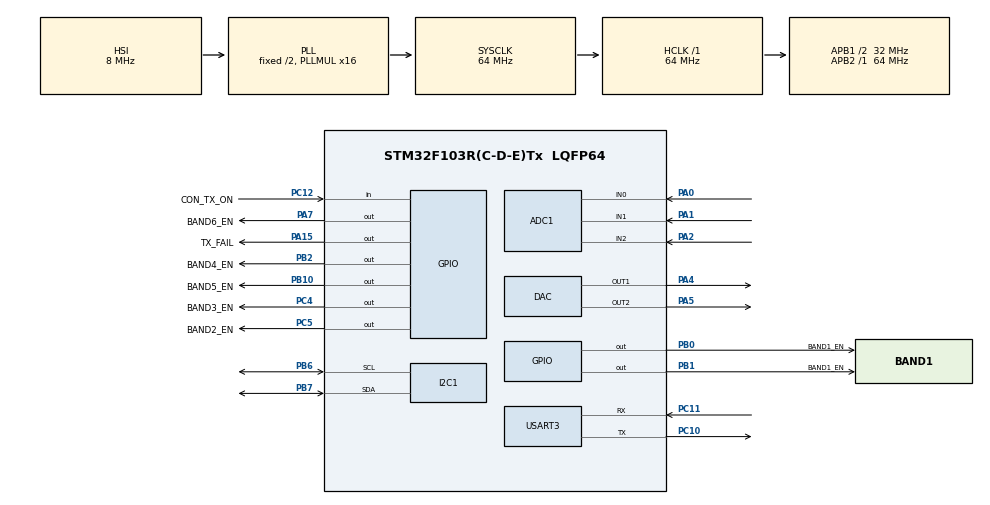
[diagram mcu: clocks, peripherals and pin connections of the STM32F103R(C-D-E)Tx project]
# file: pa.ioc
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ADC1.Channel-0\#ChannelRegularConversion=ADC_CHANNEL_0
ADC1.Channel-1\#ChannelRegularConversion=ADC_CHANNEL_0
ADC1.Channel-2\#ChannelRegularConversion=ADC_CHANNEL_0
ADC1.ExternalTrigConv=ADC_EXTERNALTRIGCONV_T3_TRGO
ADC1.NbrOfConversion=3
ADC1.NbrOfConversionFlag=1
ADC1.Rank-0\#ChannelRegularConversion=1
ADC1.Rank-1\#ChannelRegularConversion=2
ADC1.Rank-2\#ChannelRegularConversion=3
ADC1.SamplingTime-0\#ChannelRegularConversion=ADC_SAMPLETIME_13CYCLES_5
ADC1.SamplingTime-1\#ChannelRegularConversion=ADC_SAMPLETIME_13CYCLES_5
ADC1.SamplingTime-2\#ChannelRegularConversion=ADC_SAMPLETIME_13CYCLES_5
ADC1.master=1
Dma.ADC1.0.Direction=DMA_PERIPH_TO_MEMORY
Dma.ADC1.0.Instance=DMA1_Channel1
Dma.ADC1.0.MemDataAlignment=DMA_MDATAALIGN_HALFWORD
Dma.ADC1.0.MemInc=DMA_MINC_ENABLE
Dma.ADC1.0.Mode=DMA_CIRCULAR
Dma.ADC1.0.PeriphDataAlignment=DMA_PDATAALIGN_HALFWORD
Dma.ADC1.0.PeriphInc=DMA_PINC_DISABLE
Dma.ADC1.0.Priority=DMA_PRIORITY_LOW
Dma.Request0=ADC1
Dma.Request1=USART3_RX
Dma.Request2=USART3_TX
Dma.USART3_RX.1.Direction=DMA_PERIPH_TO_MEMORY
Dma.USART3_RX.1.Instance=DMA1_Channel3
Dma.USART3_RX.1.MemDataAlignment=DMA_MDATAALIGN_BYTE
Dma.USART3_RX.1.MemInc=DMA_MINC_ENABLE
Dma.USART3_RX.1.Mode=DMA_CIRCULAR
Dma.USART3_RX.1.PeriphDataAlignment=DMA_PDATAALIGN_BYTE
Dma.USART3_RX.1.PeriphInc=DMA_PINC_DISABLE
Dma.USART3_RX.1.Priority=DMA_PRIORITY_LOW
Dma.USART3_TX.2.Direction=DMA_MEMORY_TO_PERIPH
Dma.USART3_TX.2.Instance=DMA1_Channel2
Dma.USART3_TX.2.MemDataAlignment=DMA_MDATAALIGN_BYTE
Dma.USART3_TX.2.MemInc=DMA_MINC_ENABLE
Dma.USART3_TX.2.Mode=DMA_NORMAL
Dma.USART3_TX.2.PeriphDataAlignment=DMA_PDATAALIGN_BYTE
Dma.USART3_TX.2.PeriphInc=DMA_PINC_DISABLE
Dma.USART3_TX.2.Priority=DMA_PRIORITY_LOW
Mcu.Family=STM32F1
Mcu.Name=STM32F103R(C-D-E)Tx
Mcu.Package=LQFP64
NVIC.ADC1_2_IRQn=true\:5\:0\:true\:false\:true\:true\:true\:true
NVIC.DMA1_Channel1_IRQn=true\:5\:0\:true\:false\:true\:false\:true\:true
NVIC.DMA1_Channel2_IRQn=true\:6\:0\:true\:false\:true\:false\:true\:true
NVIC.DMA1_Channel3_IRQn=true\:6\:0\:true\:false\:true\:false\:true\:true
NVIC.I2C1_ER_IRQn=true\:7\:0\:true\:false\:true\:true\:true\:true
NVIC.I2C1_EV_IRQn=true\:7\:0\:true\:false\:true\:true\:true\:true
NVIC.PriorityGroup=NVIC_PRIORITYGROUP_4
PA0-WKUP.Signal=ADCx_IN0
PA1.Signal=ADCx_IN1
PA13.Mode=Trace_Asynchronous_SW
PA13.Signal=SYS_JTMS-SWDIO
PA14.Mode=Trace_Asynchronous_SW
PA14.Signal=SYS_JTCK-SWCLK
PA15.GPIO_Label=TX_FAIL
PA15.Signal=GPIO_Output
PA2.Signal=ADCx_IN2
PA4.Signal=COMP_DAC1_group
PA5.Signal=COMP_DAC2_group
PA7.GPIO_Label=BAND6_EN
PA7.Signal=GPIO_Output
PB0.GPIO_Label=BAND1_EN
PB0.Signal=GPIO_Output
PB1.GPIO_Label=BAND1_EN
PB1.Signal=GPIO_Output
PB10.GPIO_Label=BAND5_EN
PB10.Signal=GPIO_Output
PB2.GPIO_Label=BAND4_EN
PB2.Signal=GPIO_Output
PB3.Mode=Trace_Asynchronous_SW
PB3.Signal=SYS_JTDO-TRACESWO
PB6.Mode=I2C
PB6.Signal=I2C1_SCL
PB7.Mode=I2C
PB7.Signal=I2C1_SDA
PC10.Mode=Asynchronous
PC10.Signal=USART3_TX
PC11.Mode=Asynchronous
PC11.Signal=USART3_RX
PC12.GPIO_Label=CON_TX_ON
PC12.Signal=GPIO_Input
PC4.GPIO_Label=BAND3_EN
PC4.Signal=GPIO_Output
PC5.GPIO_Label=BAND2_EN
PC5.Signal=GPIO_Output
ProjectManager.HeapSize=0x200
ProjectManager.StackSize=0x400
ProjectManager.TargetToolchain=STM32CubeIDE
RCC.ADCPresc=RCC_ADCPCLK2_DIV8
RCC.AHBFreq_Value=64000000
RCC.APB1CLKDivider=RCC_HCLK_DIV2
RCC.APB1Freq_Value=32000000
RCC.APB1TimFreq_Value=64000000
RCC.APB2Freq_Value=64000000
RCC.APB2TimFreq_Value=64000000
RCC.HCLKFreq_Value=64000000
RCC.PLLMUL=RCC_PLL_MUL16
RCC.SYSCLKFreq_VALUE=64000000
RCC.SYSCLKSource=RCC_SYSCLKSOURCE_PLLCLK
RCC.USBFreq_Value=64000000
SH.ADCx_IN0.0=ADC1_IN0,IN0
SH.ADCx_IN1.0=ADC1_IN1,IN1
SH.ADCx_IN2.0=ADC1_IN2,IN2
SH.COMP_DAC1_group.0=DAC_OUT1,DAC_OUT1
SH.COMP_DAC2_group.0=DAC_OUT2,DAC_OUT2
TIM3.TIM_MasterOutputTrigger=TIM_TRGO_UPDATE
USART3.VirtualMode=VM_ASYNC
VP_TIM3_VS_ClockSourceINT.Mode=Internal
board=custom

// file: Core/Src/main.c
/* USER CODE BEGIN Header */
/**
  ******************************************************************************
  * @file           : main.c
  * @brief          : Main program body
  ******************************************************************************
  * @attention
  *
  * Copyright (c) 2025 STMicroelectronics.
  * All rights reserved.
  *
  * This software is licensed under terms that can be found in the LICENSE file
  * in the root directory of this software component.
  * If no LICENSE file comes with this software, it is provided AS-IS.
  *
  ******************************************************************************
  */
/* USER CODE END Header */
#include "main.h"

/* USER CODE BEGIN Includes */
#include "cmd.h"
#include "adc.h"
#include "gpio.h"
#include "max6651.h"
/* USER CODE END Includes */

ADC_HandleTypeDef hadc1;
DMA_HandleTypeDef hdma_adc1;

DAC_HandleTypeDef hdac;

I2C_HandleTypeDef hi2c1;

TIM_HandleTypeDef htim3;

UART_HandleTypeDef huart3;
DMA_HandleTypeDef hdma_usart3_rx;
DMA_HandleTypeDef hdma_usart3_tx;

void SystemClock_Config(void);
static void MX_GPIO_Init(void);
static void MX_DMA_Init(void);
static void MX_ADC1_Init(void);
static void MX_DAC_Init(void);
static void MX_I2C1_Init(void);
static void MX_USART3_UART_Init(void);
static void MX_TIM3_Init(void);

int main(void)
{

  /* MCU Configuration--------------------------------------------------------*/

  /* Reset of all peripherals, Initializes the Flash interface and the Systick. */
  HAL_Init();

  /* Configure the system clock */
  SystemClock_Config();

  /* Initialize all configured peripherals */
  MX_GPIO_Init();
  MX_DMA_Init();
  MX_ADC1_Init();
  MX_DAC_Init();
  MX_I2C1_Init();
  MX_USART3_UART_Init();
  MX_TIM3_Init();
  /* USER CODE BEGIN 2 */
  gpio_tx_off();
  max6651_init();
  cmd_start();
  adc_start();

  HAL_DAC_SetValue(&hdac, DAC_CHANNEL_1, DAC_ALIGN_12B_R, 0);
  HAL_DAC_SetValue(&hdac, DAC_CHANNEL_2, DAC_ALIGN_12B_R, 0);
  HAL_DAC_Start(&hdac, DAC_CHANNEL_1);
  HAL_DAC_Start(&hdac, DAC_CHANNEL_2);

  /* USER CODE END 2 */
//  gpio_tx_on();
  /* Infinite loop */
  while (1)
  {

    /* USER CODE BEGIN 3 */
	  cmd_tick();
	  adc_tick();
	  gpio_tick();
	  max6651_tick();
  }
  /* USER CODE END 3 */
}

void SystemClock_Config(void)
{
  RCC_OscInitTypeDef RCC_OscInitStruct = {0};
  RCC_ClkInitTypeDef RCC_ClkInitStruct = {0};
  RCC_PeriphCLKInitTypeDef PeriphClkInit = {0};

  /** Initializes the RCC Oscillators according to the specified parameters
  * in the RCC_OscInitTypeDef structure.
  */
  RCC_OscInitStruct.OscillatorType = RCC_OSCILLATORTYPE_HSI;
  RCC_OscInitStruct.HSIState = RCC_HSI_ON;
  RCC_OscInitStruct.HSICalibrationValue = RCC_HSICALIBRATION_DEFAULT;
  RCC_OscInitStruct.PLL.PLLState = RCC_PLL_ON;
  RCC_OscInitStruct.PLL.PLLSource = RCC_PLLSOURCE_HSI_DIV2;
  RCC_OscInitStruct.PLL.PLLMUL = RCC_PLL_MUL16;
  if (HAL_RCC_OscConfig(&RCC_OscInitStruct) != HAL_OK)
  {
    Error_Handler();
  }

  /** Initializes the CPU, AHB and APB buses clocks
  */
  RCC_ClkInitStruct.ClockType = RCC_CLOCKTYPE_HCLK|RCC_CLOCKTYPE_SYSCLK
                              |RCC_CLOCKTYPE_PCLK1|RCC_CLOCKTYPE_PCLK2;
  RCC_ClkInitStruct.SYSCLKSource = RCC_SYSCLKSOURCE_PLLCLK;
  RCC_ClkInitStruct.AHBCLKDivider = RCC_SYSCLK_DIV1;
  RCC_ClkInitStruct.APB1CLKDivider = RCC_HCLK_DIV2;
  RCC_ClkInitStruct.APB2CLKDivider = RCC_HCLK_DIV1;

  if (HAL_RCC_ClockConfig(&RCC_ClkInitStruct, FLASH_LATENCY_2) != HAL_OK)
  {
    Error_Handler();
  }
  PeriphClkInit.PeriphClockSelection = RCC_PERIPHCLK_ADC;
  PeriphClkInit.AdcClockSelection = RCC_ADCPCLK2_DIV8;
  if (HAL_RCCEx_PeriphCLKConfig(&PeriphClkInit) != HAL_OK)
  {
    Error_Handler();
  }
}

static void MX_ADC1_Init(void)
{

  ADC_ChannelConfTypeDef sConfig = {0};

  /** Common config
  */
  hadc1.Instance = ADC1;
  hadc1.Init.ScanConvMode = ADC_SCAN_ENABLE;
  hadc1.Init.ContinuousConvMode = DISABLE;
  hadc1.Init.DiscontinuousConvMode = DISABLE;
  hadc1.Init.ExternalTrigConv = ADC_EXTERNALTRIGCONV_T3_TRGO;
  hadc1.Init.DataAlign = ADC_DATAALIGN_RIGHT;
  hadc1.Init.NbrOfConversion = 3;
  if (HAL_ADC_Init(&hadc1) != HAL_OK)
  {
    Error_Handler();
  }

  /** Configure Regular Channel
  */
  sConfig.Channel = ADC_CHANNEL_0;
  sConfig.Rank = ADC_REGULAR_RANK_1;
  sConfig.SamplingTime = ADC_SAMPLETIME_13CYCLES_5;
  if (HAL_ADC_ConfigChannel(&hadc1, &sConfig) != HAL_OK)
  {
    Error_Handler();
  }

  /** Configure Regular Channel
  */
  sConfig.Channel = ADC_CHANNEL_1;
  sConfig.Rank = ADC_REGULAR_RANK_2;
  if (HAL_ADC_ConfigChannel(&hadc1, &sConfig) != HAL_OK)
  {
    Error_Handler();
  }

  /** Configure Regular Channel
  */
  sConfig.Channel = ADC_CHANNEL_2;
  sConfig.Rank = ADC_REGULAR_RANK_3;
  if (HAL_ADC_ConfigChannel(&hadc1, &sConfig) != HAL_OK)
  {
    Error_Handler();
  }

}

static void MX_DAC_Init(void)
{

  DAC_ChannelConfTypeDef sConfig = {0};

  /** DAC Initialization
  */
  hdac.Instance = DAC;
  if (HAL_DAC_Init(&hdac) != HAL_OK)
  {
    Error_Handler();
  }

  /** DAC channel OUT1 config
  */
  sConfig.DAC_Trigger = DAC_TRIGGER_NONE;
  sConfig.DAC_OutputBuffer = DAC_OUTPUTBUFFER_ENABLE;
  if (HAL_DAC_ConfigChannel(&hdac, &sConfig, DAC_CHANNEL_1) != HAL_OK)
  {
    Error_Handler();
  }

  /** DAC channel OUT2 config
  */
  if (HAL_DAC_ConfigChannel(&hdac, &sConfig, DAC_CHANNEL_2) != HAL_OK)
  {
    Error_Handler();
  }

}

static void MX_I2C1_Init(void)
{

  hi2c1.Instance = I2C1;
  hi2c1.Init.ClockSpeed = 100000;
  hi2c1.Init.DutyCycle = I2C_DUTYCYCLE_2;
  hi2c1.Init.OwnAddress1 = 0;
  hi2c1.Init.AddressingMode = I2C_ADDRESSINGMODE_7BIT;
  hi2c1.Init.DualAddressMode = I2C_DUALADDRESS_DISABLE;
  hi2c1.Init.OwnAddress2 = 0;
  hi2c1.Init.GeneralCallMode = I2C_GENERALCALL_DISABLE;
  hi2c1.Init.NoStretchMode = I2C_NOSTRETCH_DISABLE;
  if (HAL_I2C_Init(&hi2c1) != HAL_OK)
  {
    Error_Handler();
  }

}

static void MX_TIM3_Init(void)
{

  TIM_ClockConfigTypeDef sClockSourceConfig = {0};
  TIM_MasterConfigTypeDef sMasterConfig = {0};

  htim3.Instance = TIM3;
  htim3.Init.Prescaler = 0;
  htim3.Init.CounterMode = TIM_COUNTERMODE_UP;
  htim3.Init.Period = 65535;
  htim3.Init.ClockDivision = TIM_CLOCKDIVISION_DIV1;
  htim3.Init.AutoReloadPreload = TIM_AUTORELOAD_PRELOAD_DISABLE;
  if (HAL_TIM_Base_Init(&htim3) != HAL_OK)
  {
    Error_Handler();
  }
  sClockSourceConfig.ClockSource = TIM_CLOCKSOURCE_INTERNAL;
  if (HAL_TIM_ConfigClockSource(&htim3, &sClockSourceConfig) != HAL_OK)
  {
    Error_Handler();
  }
  sMasterConfig.MasterOutputTrigger = TIM_TRGO_UPDATE;
  sMasterConfig.MasterSlaveMode = TIM_MASTERSLAVEMODE_DISABLE;
  if (HAL_TIMEx_MasterConfigSynchronization(&htim3, &sMasterConfig) != HAL_OK)
  {
    Error_Handler();
  }

}

static void MX_USART3_UART_Init(void)
{

  huart3.Instance = USART3;
  huart3.Init.BaudRate = 115200;
  huart3.Init.WordLength = UART_WORDLENGTH_8B;
  huart3.Init.StopBits = UART_STOPBITS_1;
  huart3.Init.Parity = UART_PARITY_NONE;
  huart3.Init.Mode = UART_MODE_TX_RX;
  huart3.Init.HwFlowCtl = UART_HWCONTROL_NONE;
  huart3.Init.OverSampling = UART_OVERSAMPLING_16;
  if (HAL_UART_Init(&huart3) != HAL_OK)
  {
    Error_Handler();
  }

}

static void MX_DMA_Init(void)
{

  /* DMA controller clock enable */
  __HAL_RCC_DMA1_CLK_ENABLE();

  /* DMA interrupt init */
  /* DMA1_Channel1_IRQn interrupt configuration */
  HAL_NVIC_SetPriority(DMA1_Channel1_IRQn, 5, 0);
  HAL_NVIC_EnableIRQ(DMA1_Channel1_IRQn);
  /* DMA1_Channel2_IRQn interrupt configuration */
  HAL_NVIC_SetPriority(DMA1_Channel2_IRQn, 6, 0);
  HAL_NVIC_EnableIRQ(DMA1_Channel2_IRQn);
  /* DMA1_Channel3_IRQn interrupt configuration */
  HAL_NVIC_SetPriority(DMA1_Channel3_IRQn, 6, 0);
  HAL_NVIC_EnableIRQ(DMA1_Channel3_IRQn);

}

static void MX_GPIO_Init(void)
{
  GPIO_InitTypeDef GPIO_InitStruct = {0};

  /* GPIO Ports Clock Enable */
  __HAL_RCC_GPIOA_CLK_ENABLE();
  __HAL_RCC_GPIOC_CLK_ENABLE();
  __HAL_RCC_GPIOB_CLK_ENABLE();

  /*Configure GPIO pin Output Level */
  HAL_GPIO_WritePin(GPIOA, BAND6_EN_Pin|TX_FAIL_Pin, GPIO_PIN_RESET);

  /*Configure GPIO pin Output Level */
  HAL_GPIO_WritePin(GPIOC, BAND2_EN_Pin|BAND3_EN_Pin, GPIO_PIN_RESET);

  /*Configure GPIO pin Output Level */
  HAL_GPIO_WritePin(GPIOB, BAND0_EN_Pin|BAND1_EN_Pin|BAND4_EN_Pin|BAND5_EN_Pin, GPIO_PIN_RESET);

  /*Configure GPIO pins : BAND6_EN_Pin BAND5_EN_Pin TX_FAIL_Pin */
  GPIO_InitStruct.Pin = BAND6_EN_Pin|TX_FAIL_Pin;
  GPIO_InitStruct.Mode = GPIO_MODE_OUTPUT_PP;
  GPIO_InitStruct.Pull = GPIO_NOPULL;
  GPIO_InitStruct.Speed = GPIO_SPEED_FREQ_LOW;
  HAL_GPIO_Init(GPIOA, &GPIO_InitStruct);

  /*Configure GPIO pins : BAND4_EN_Pin BAND3_EN_Pin */
  GPIO_InitStruct.Pin = BAND2_EN_Pin|BAND3_EN_Pin;
  GPIO_InitStruct.Mode = GPIO_MODE_OUTPUT_PP;
  GPIO_InitStruct.Pull = GPIO_NOPULL;
  GPIO_InitStruct.Speed = GPIO_SPEED_FREQ_LOW;
  HAL_GPIO_Init(GPIOC, &GPIO_InitStruct);

  /*Configure GPIO pins : BAND2_EN_Pin BAND1_EN_Pin BAND0_EN_Pin */
  GPIO_InitStruct.Pin = BAND0_EN_Pin|BAND1_EN_Pin|BAND4_EN_Pin|BAND5_EN_Pin;
  GPIO_InitStruct.Mode = GPIO_MODE_OUTPUT_PP;
  GPIO_InitStruct.Pull = GPIO_NOPULL;
  GPIO_InitStruct.Speed = GPIO_SPEED_FREQ_LOW;
  HAL_GPIO_Init(GPIOB, &GPIO_InitStruct);

  /*Configure GPIO pin : CON_TX_ON_Pin */
  GPIO_InitStruct.Pin = CON_TX_ON_Pin;
  GPIO_InitStruct.Mode = GPIO_MODE_INPUT;
  GPIO_InitStruct.Pull = GPIO_NOPULL;
  HAL_GPIO_Init(CON_TX_ON_GPIO_Port, &GPIO_InitStruct);

}

void Error_Handler(void)
{
  __disable_irq();
  while (1)
  {
  }
}
